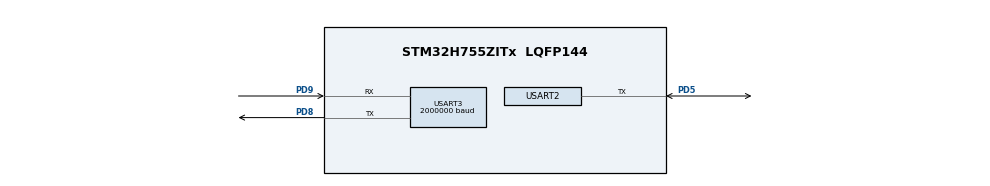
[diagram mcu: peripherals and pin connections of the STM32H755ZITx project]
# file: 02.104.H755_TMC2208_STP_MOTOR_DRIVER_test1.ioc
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CortexM4.IPs=FATFS_M4\:I,FREERTOS_M4\:I,IWDG2\:I,RCC,WWDG2\:I,DMA,BDMA,MDMA,NVIC2\:I,ETH,DEBUG,PDM2PCM_M4\:I,PWR,RESMGR_UTILITY,SYS_M4\:I,USB_DEVICE_M4\:I,USB_HOST_M4\:I,CORTEX_M4\:I,GPIO,OPENAMP_M4\:I,VREFBUF,NUCLEO-H755ZI-Q
CortexM7.IPs=FATFS_M7\:I,FREERTOS_M7\:I,IWDG1\:I,RCC\:I,WWDG1\:I,DMA\:I,BDMA\:I,MDMA\:I,NVIC1\:I,ETH\:I,USART3\:I,USB_OTG_FS\:I,SYS\:I,CORTEX_M7\:I,DEBUG\:I,PDM2PCM_M7\:I,PWR\:I,RESMGR_UTILITY\:I,USB_DEVICE_M7\:I,USB_HOST_M7\:I,GPIO\:I,OPENAMP_M7\:I,VREFBUF\:I,NUCLEO-H755ZI-Q\:I,USART2\:I
Dma.Request0=USART3_TX
Dma.Request1=USART3_RX
Dma.USART3_RX.1.Direction=DMA_PERIPH_TO_MEMORY
Dma.USART3_RX.1.EventEnable=DISABLE
Dma.USART3_RX.1.FIFOMode=DMA_FIFOMODE_DISABLE
Dma.USART3_RX.1.Instance=DMA1_Stream1
Dma.USART3_RX.1.MemDataAlignment=DMA_MDATAALIGN_BYTE
Dma.USART3_RX.1.MemInc=DMA_MINC_ENABLE
Dma.USART3_RX.1.Mode=DMA_CIRCULAR
Dma.USART3_RX.1.PeriphDataAlignment=DMA_PDATAALIGN_BYTE
Dma.USART3_RX.1.PeriphInc=DMA_PINC_DISABLE
Dma.USART3_RX.1.Polarity=HAL_DMAMUX_REQ_GEN_RISING
Dma.USART3_RX.1.Priority=DMA_PRIORITY_LOW
Dma.USART3_RX.1.RequestNumber=1
Dma.USART3_RX.1.SignalID=NONE
Dma.USART3_RX.1.SyncEnable=DISABLE
Dma.USART3_RX.1.SyncPolarity=HAL_DMAMUX_SYNC_NO_EVENT
Dma.USART3_RX.1.SyncRequestNumber=1
Dma.USART3_RX.1.SyncSignalID=NONE
Dma.USART3_TX.0.Direction=DMA_MEMORY_TO_PERIPH
Dma.USART3_TX.0.EventEnable=DISABLE
Dma.USART3_TX.0.FIFOMode=DMA_FIFOMODE_DISABLE
Dma.USART3_TX.0.Instance=DMA1_Stream0
Dma.USART3_TX.0.MemDataAlignment=DMA_MDATAALIGN_BYTE
Dma.USART3_TX.0.MemInc=DMA_MINC_ENABLE
Dma.USART3_TX.0.Mode=DMA_NORMAL
Dma.USART3_TX.0.PeriphDataAlignment=DMA_PDATAALIGN_BYTE
Dma.USART3_TX.0.PeriphInc=DMA_PINC_DISABLE
Dma.USART3_TX.0.Polarity=HAL_DMAMUX_REQ_GEN_RISING
Dma.USART3_TX.0.Priority=DMA_PRIORITY_LOW
Dma.USART3_TX.0.RequestNumber=1
Dma.USART3_TX.0.SignalID=NONE
Dma.USART3_TX.0.SyncEnable=DISABLE
Dma.USART3_TX.0.SyncPolarity=HAL_DMAMUX_SYNC_NO_EVENT
Dma.USART3_TX.0.SyncRequestNumber=1
Dma.USART3_TX.0.SyncSignalID=NONE
Mcu.Family=STM32H7
Mcu.Name=STM32H755ZITx
Mcu.Package=LQFP144
NVIC1.DMA1_Stream0_IRQn=true\:1\:0\:true\:false\:true\:false\:true\:true
NVIC1.DMA1_Stream1_IRQn=true\:1\:0\:true\:false\:true\:false\:true\:true
NVIC1.PriorityGroup=NVIC_PRIORITYGROUP_4
NVIC1.USART2_IRQn=true\:0\:0\:false\:false\:true\:true\:true\:true
NVIC1.USART3_IRQn=true\:1\:0\:true\:false\:true\:true\:true\:true
NVIC2.PriorityGroup=NVIC_PRIORITYGROUP_4
PB0.TagName=LD1
PB14.TagName=LD3
PB6.PinAttribute=CortexM7
PB6.Signal=USART1_TX
PB7.PinAttribute=CortexM7
PB7.Signal=USART1_RX
PC13.TagName=BUTTON
PD5.GPIO_Speed=GPIO_SPEED_FREQ_VERY_HIGH
PD5.Mode=Half_duplex(single_wire_mode)
PD5.PinAttribute=CortexM7
PD5.Signal=USART2_TX
PD6.GPIO_PuPd=GPIO_NOPULL
PD6.GPIO_Speed=GPIO_SPEED_FREQ_VERY_HIGH
PD6.PinAttribute=CortexM7
PD6.Signal=USART2_RX
PD8.Mode=Asynchronous
PD8.PinAttribute=CortexM7
PD8.Signal=USART3_TX
PD8.TagName=VCP_RX
PD9.Mode=Asynchronous
PD9.PinAttribute=CortexM7
PD9.Signal=USART3_RX
PD9.TagName=VCP_TX
PE1.TagName=LD2
ProjectManager.HeapSize=M4-0x200,M7-0x200
ProjectManager.StackSize=M4-0x400,M7-0x400
ProjectManager.TargetToolchain=STM32CubeIDE
RCC.ADCFreq_Value=129000000
RCC.APB1Freq_Value=100000000
RCC.APB2Freq_Value=100000000
RCC.APB3Freq_Value=100000000
RCC.APB4Freq_Value=100000000
RCC.CortexFreq_Value=400000000
RCC.D1PPRE=RCC_APB3_DIV2
RCC.D2PPRE1=RCC_APB1_DIV2
RCC.D2PPRE2=RCC_APB2_DIV2
RCC.D3PPRE=RCC_APB4_DIV2
RCC.DIVM1=4
RCC.DIVN1=50
RCC.DIVQ1=5
RCC.HCLKFreq_Value=200000000
RCC.HPRE=RCC_HCLK_DIV2
RCC.PLL2FRACN=0
RCC.PLL3FRACN=0
RCC.PLLFRACN=0
RCC.SYSCLKFreq_VALUE=400000000
RCC.SYSCLKSource=RCC_SYSCLKSOURCE_PLLCLK
RCC.SupplySource=PWR_DIRECT_SMPS_SUPPLY
RCC.USBFreq_Value=160000000
USART2.VirtualMode-Half_duplex(single_wire_mode)=VM_ASYNC
USART3.BaudRate=2000000
USART3.VirtualMode-Asynchronous=VM_ASYNC
VP_SYS_M4_VS_Systick.Mode=SysTick
board=NUCLEO-H755ZI-Q

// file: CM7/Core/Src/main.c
/* USER CODE BEGIN Header */
/**
  ******************************************************************************
  * @file           : main.c
  * @brief          : Main program body
  ******************************************************************************
  * @attention
  *
  * Copyright (c) 2025 STMicroelectronics.
  * All rights reserved.
  *
  * This software is licensed under terms that can be found in the LICENSE file
  * in the root directory of this software component.
  * If no LICENSE file comes with this software, it is provided AS-IS.
  *
  ******************************************************************************
  */
/* USER CODE END Header */
#include "main.h"

/* USER CODE BEGIN Includes */
#include <stdio.h>
#include <string.h>
#include <stddef.h>
#include <stdarg.h>
#include <stdbool.h>
#include <stdlib.h>
/* USER CODE END Includes */

/* USER CODE BEGIN PD */

/* DUAL_CORE_BOOT_SYNC_SEQUENCE: Define for dual core boot synchronization    */
/*                             demonstration code based on hardware semaphore */
/* This define is present in both CM7/CM4 projects                            */
/* To comment when developping/debugging on a single core                     */
#define DUAL_CORE_BOOT_SYNC_SEQUENCE

#if defined(DUAL_CORE_BOOT_SYNC_SEQUENCE)
#ifndef HSEM_ID_0
#define HSEM_ID_0 (0U) /* HW semaphore 0*/
#endif
#endif /* DUAL_CORE_BOOT_SYNC_SEQUENCE */

/* USER CODE END PD */

UART_HandleTypeDef huart4;
UART_HandleTypeDef huart3;
DMA_HandleTypeDef hdma_usart3_tx;
DMA_HandleTypeDef hdma_usart3_rx;

/* USER CODE BEGIN PV */
uint8_t dma_rx_buffer[64];
uint8_t dma_tx_buffer[64];
uint16_t old_pos = 0;

static volatile bool uart_tx_busy = false;
static char uartBuffer[250];

typedef enum
{
    TMC_IDLE,
    TMC_TX,
    TMC_WAIT_TURNAROUND,
    TMC_RX,
    TMC_DONE,
    TMC_ERROR
} TMC_State_t;

volatile TMC_State_t tmcState = TMC_IDLE;
uint32_t tmcTimestamp;

uint8_t tmc_tx[8];
uint8_t tmc_rx[8];

/* USER CODE END PV */

void SystemClock_Config(void);
static void MX_GPIO_Init(void);
static void MX_DMA_Init(void);
static void MX_USART3_UART_Init(void);
static void MX_USART2_UART_Init(void);

/* USER CODE BEGIN 0 */
void DebugPrint(const char *format, ...)
{
	// Wait for previous transmission to complete
	    while (uart_tx_busy);

	    va_list args;
	    va_start(args, format);
	    vsnprintf(uartBuffer, sizeof(uartBuffer), format, args);
	    va_end(args);

	    uart_tx_busy = true;

	    HAL_UART_Transmit_DMA(&huart3, (uint8_t *)uartBuffer, strlen(uartBuffer));
}

void UART2_TX_Output(void)
{
    GPIO_InitTypeDef GPIO_InitStruct = {0};

    GPIO_InitStruct.Pin       = GPIO_PIN_5;
    GPIO_InitStruct.Mode      = GPIO_MODE_AF_PP;
    GPIO_InitStruct.Pull      = GPIO_NOPULL;
    GPIO_InitStruct.Speed     = GPIO_SPEED_FREQ_HIGH;
    GPIO_InitStruct.Alternate = GPIO_AF7_USART2;

    HAL_GPIO_Init(GPIOD, &GPIO_InitStruct);
}

void UART2_TX_Input(void)
{
    GPIO_InitTypeDef GPIO_InitStruct = {0};

    GPIO_InitStruct.Pin  = GPIO_PIN_5;
    GPIO_InitStruct.Mode = GPIO_MODE_INPUT;
    GPIO_InitStruct.Pull = GPIO_NOPULL;

    HAL_GPIO_Init(GPIOD, &GPIO_InitStruct);
}

void parse_tmc_response(uint8_t *data)
{
	DebugPrint("TMC: ");
    for (int i = 0; i < 8; i++)
    	DebugPrint("%02X ", data[i]);
    DebugPrint("\r\n");
}

uint8_t tmc2208_crc(uint8_t *data, uint8_t len)
{
    uint8_t crc = 0;

    for (uint8_t i = 0; i < len; i++)
    {
        uint8_t current = data[i];
        for (uint8_t bit = 0; bit < 8; bit++)
        {
            if ((crc ^ current) & 0x01)
                crc = (crc >> 1) ^ 0x8C;
            else
                crc >>= 1;

            current >>= 1;
        }
    }
    return crc;
}

void build_tmc_frame(uint8_t *buf)
{
    buf[0] = 0x05;     // SYNC
    buf[1] = 0x00;     // Slave address
    buf[2] = 0x00;     // GCONF
    buf[3] = 0x00;
    buf[4] = 0x00;
    buf[5] = 0x00;
    buf[6] = 0x00;

    buf[7] = 0x07;
//    buf[7] = tmc2208_crc(buf, 7);
}

void TMC2208_StartRead(void)
{
    if (tmcState == TMC_IDLE)
    {
        build_tmc_frame(tmc_tx);
        tmcState = TMC_TX;
    }
}

void check_dma_data(void)
{
    static uint32_t total_pos = 0;  // new: global linear counter

    uint16_t pos = sizeof(dma_rx_buffer) - __HAL_DMA_GET_COUNTER(&hdma_usart3_rx);

    if (pos != old_pos)
    {
        if (pos > old_pos)
        {
            // Normal forward move (no wrap)
            for (uint16_t i = old_pos; i < pos; i++)
            {
                DebugPrint("\r\nGot: '%c' (0x%02X) at pos %lu\r\n\r\n",
                           dma_rx_buffer[i], dma_rx_buffer[i], total_pos++);
            }
        }
        else
        {
            // Wrapped around — handle end part and restart from 0
            for (uint16_t i = old_pos; i < sizeof(dma_rx_buffer); i++)
            {
                DebugPrint("\r\nGot: '%c' (0x%02X) at pos %lu\r\n\r\n",
                           dma_rx_buffer[i], dma_rx_buffer[i], total_pos++);
            }
            for (uint16_t i = 0; i < pos; i++)
            {
                DebugPrint("\r\nGot: '%c' (0x%02X) at pos %lu\r\n\r\n",
                           dma_rx_buffer[i], dma_rx_buffer[i], total_pos++);
            }
        }

        old_pos = pos;
    }
}

void TMC2208_Process(void)
{
    switch (tmcState)
    {
        case TMC_IDLE:
            break;

        case TMC_TX:
            UART2_TX_Output();
            HAL_UART_Transmit_IT(&huart4, tmc_tx, 8);
            break;

        case TMC_WAIT_TURNAROUND:
            if ((HAL_GetTick() - tmcTimestamp) >= 5)
            {
            	DebugPrint("C\n\r");
                UART2_TX_Input();
                HAL_UART_Receive_IT(&huart4, tmc_rx, 8);
                tmcState = TMC_RX;
                DebugPrint("D\n\r");
            }
            break;

        case TMC_RX:
            /* wait for callback */
            break;

        case TMC_DONE:
            parse_tmc_response(tmc_rx);

            DebugPrint("E\n\r");
            tmcState = TMC_IDLE;
            break;

        case TMC_ERROR:
            tmcState = TMC_IDLE;
            break;
    }
}

/* USER CODE END 0 */

int main(void)
{

/* USER CODE BEGIN Boot_Mode_Sequence_0 */
#if defined(DUAL_CORE_BOOT_SYNC_SEQUENCE)
  int32_t timeout;
#endif /* DUAL_CORE_BOOT_SYNC_SEQUENCE */
/* USER CODE END Boot_Mode_Sequence_0 */

/* USER CODE BEGIN Boot_Mode_Sequence_1 */
#if defined(DUAL_CORE_BOOT_SYNC_SEQUENCE)
  /* Wait until CPU2 boots and enters in stop mode or timeout*/
  timeout = 0xFFFF;
  while((__HAL_RCC_GET_FLAG(RCC_FLAG_D2CKRDY) != RESET) && (timeout-- > 0));
  if ( timeout < 0 )
  {
  Error_Handler();
  }
#endif /* DUAL_CORE_BOOT_SYNC_SEQUENCE */
/* USER CODE END Boot_Mode_Sequence_1 */
  /* MCU Configuration--------------------------------------------------------*/

  /* Reset of all peripherals, Initializes the Flash interface and the Systick. */
  HAL_Init();

  /* Configure the system clock */
  SystemClock_Config();
/* USER CODE BEGIN Boot_Mode_Sequence_2 */
#if defined(DUAL_CORE_BOOT_SYNC_SEQUENCE)
/* When system initialization is finished, Cortex-M7 will release Cortex-M4 by means of
HSEM notification */
/*HW semaphore Clock enable*/
__HAL_RCC_HSEM_CLK_ENABLE();
/*Take HSEM */
HAL_HSEM_FastTake(HSEM_ID_0);
/*Release HSEM in order to notify the CPU2(CM4)*/
HAL_HSEM_Release(HSEM_ID_0,0);
/* wait until CPU2 wakes up from stop mode */
timeout = 0xFFFF;
while((__HAL_RCC_GET_FLAG(RCC_FLAG_D2CKRDY) == RESET) && (timeout-- > 0));
if ( timeout < 0 )
{
Error_Handler();
}
#endif /* DUAL_CORE_BOOT_SYNC_SEQUENCE */
/* USER CODE END Boot_Mode_Sequence_2 */

  /* Initialize all configured peripherals */
  MX_GPIO_Init();
  MX_DMA_Init();
  MX_USART3_UART_Init();
  MX_USART2_UART_Init();
  /* USER CODE BEGIN 2 */
  DebugPrint("\r\n=== UART DMA RX Circular + TX Normal ===\r\n");

  HAL_UART_Receive_DMA(&huart3, dma_rx_buffer, sizeof(dma_rx_buffer));

  uint8_t test[7] = {0x05,0x00,0x00,0x00,0x00,0x00,0x00};
  uint8_t crc = tmc2208_crc(test, 7);

  DebugPrint("crc: %x\n\r",crc);

  /* USER CODE END 2 */

  /* Infinite loop */
  while (1)
  {

    /* USER CODE BEGIN 3 */
	  check_dma_data();

      TMC2208_Process();

      /* Trigger read periodically */
      static uint32_t last = 0;
      if (HAL_GetTick() - last > 100)
      {
          last = HAL_GetTick();
          TMC2208_StartRead();
      }
  }
  /* USER CODE END 3 */
}

void SystemClock_Config(void)
{
  RCC_OscInitTypeDef RCC_OscInitStruct = {0};
  RCC_ClkInitTypeDef RCC_ClkInitStruct = {0};

  /** Supply configuration update enable
  */
  HAL_PWREx_ConfigSupply(PWR_DIRECT_SMPS_SUPPLY);

  /** Configure the main internal regulator output voltage
  */
  __HAL_PWR_VOLTAGESCALING_CONFIG(PWR_REGULATOR_VOLTAGE_SCALE1);

  while(!__HAL_PWR_GET_FLAG(PWR_FLAG_VOSRDY)) {}

  /** Initializes the RCC Oscillators according to the specified parameters
  * in the RCC_OscInitTypeDef structure.
  */
  RCC_OscInitStruct.OscillatorType = RCC_OSCILLATORTYPE_HSI;
  RCC_OscInitStruct.HSIState = RCC_HSI_DIV1;
  RCC_OscInitStruct.HSICalibrationValue = RCC_HSICALIBRATION_DEFAULT;
  RCC_OscInitStruct.PLL.PLLState = RCC_PLL_ON;
  RCC_OscInitStruct.PLL.PLLSource = RCC_PLLSOURCE_HSI;
  RCC_OscInitStruct.PLL.PLLM = 4;
  RCC_OscInitStruct.PLL.PLLN = 50;
  RCC_OscInitStruct.PLL.PLLP = 2;
  RCC_OscInitStruct.PLL.PLLQ = 5;
  RCC_OscInitStruct.PLL.PLLR = 2;
  RCC_OscInitStruct.PLL.PLLRGE = RCC_PLL1VCIRANGE_3;
  RCC_OscInitStruct.PLL.PLLVCOSEL = RCC_PLL1VCOWIDE;
  RCC_OscInitStruct.PLL.PLLFRACN = 0;
  if (HAL_RCC_OscConfig(&RCC_OscInitStruct) != HAL_OK)
  {
    Error_Handler();
  }

  /** Initializes the CPU, AHB and APB buses clocks
  */
  RCC_ClkInitStruct.ClockType = RCC_CLOCKTYPE_HCLK|RCC_CLOCKTYPE_SYSCLK
                              |RCC_CLOCKTYPE_PCLK1|RCC_CLOCKTYPE_PCLK2
                              |RCC_CLOCKTYPE_D3PCLK1|RCC_CLOCKTYPE_D1PCLK1;
  RCC_ClkInitStruct.SYSCLKSource = RCC_SYSCLKSOURCE_PLLCLK;
  RCC_ClkInitStruct.SYSCLKDivider = RCC_SYSCLK_DIV1;
  RCC_ClkInitStruct.AHBCLKDivider = RCC_HCLK_DIV2;
  RCC_ClkInitStruct.APB3CLKDivider = RCC_APB3_DIV2;
  RCC_ClkInitStruct.APB1CLKDivider = RCC_APB1_DIV2;
  RCC_ClkInitStruct.APB2CLKDivider = RCC_APB2_DIV2;
  RCC_ClkInitStruct.APB4CLKDivider = RCC_APB4_DIV2;

  if (HAL_RCC_ClockConfig(&RCC_ClkInitStruct, FLASH_LATENCY_2) != HAL_OK)
  {
    Error_Handler();
  }
}

static void MX_USART2_UART_Init(void)
{

  huart4.Instance = USART2;
  huart4.Init.BaudRate = 115200;
  huart4.Init.WordLength = UART_WORDLENGTH_8B;
  huart4.Init.StopBits = UART_STOPBITS_1;
  huart4.Init.Parity = UART_PARITY_NONE;
  huart4.Init.Mode = UART_MODE_TX_RX;
  huart4.Init.HwFlowCtl = UART_HWCONTROL_NONE;
  huart4.Init.OverSampling = UART_OVERSAMPLING_16;
  huart4.Init.OneBitSampling = UART_ONE_BIT_SAMPLE_DISABLE;
  huart4.Init.ClockPrescaler = UART_PRESCALER_DIV1;
  huart4.AdvancedInit.AdvFeatureInit = UART_ADVFEATURE_NO_INIT;
  if (HAL_HalfDuplex_Init(&huart4) != HAL_OK)
  {
    Error_Handler();
  }
  if (HAL_UARTEx_SetTxFifoThreshold(&huart4, UART_TXFIFO_THRESHOLD_1_8) != HAL_OK)
  {
    Error_Handler();
  }
  if (HAL_UARTEx_SetRxFifoThreshold(&huart4, UART_RXFIFO_THRESHOLD_1_8) != HAL_OK)
  {
    Error_Handler();
  }
  if (HAL_UARTEx_DisableFifoMode(&huart4) != HAL_OK)
  {
    Error_Handler();
  }

}

static void MX_USART3_UART_Init(void)
{

  huart3.Instance = USART3;
  huart3.Init.BaudRate = 2000000;
  huart3.Init.WordLength = UART_WORDLENGTH_8B;
  huart3.Init.StopBits = UART_STOPBITS_1;
  huart3.Init.Parity = UART_PARITY_NONE;
  huart3.Init.Mode = UART_MODE_TX_RX;
  huart3.Init.HwFlowCtl = UART_HWCONTROL_NONE;
  huart3.Init.OverSampling = UART_OVERSAMPLING_16;
  huart3.Init.OneBitSampling = UART_ONE_BIT_SAMPLE_DISABLE;
  huart3.Init.ClockPrescaler = UART_PRESCALER_DIV1;
  huart3.AdvancedInit.AdvFeatureInit = UART_ADVFEATURE_NO_INIT;
  if (HAL_UART_Init(&huart3) != HAL_OK)
  {
    Error_Handler();
  }
  if (HAL_UARTEx_SetTxFifoThreshold(&huart3, UART_TXFIFO_THRESHOLD_1_8) != HAL_OK)
  {
    Error_Handler();
  }
  if (HAL_UARTEx_SetRxFifoThreshold(&huart3, UART_RXFIFO_THRESHOLD_1_8) != HAL_OK)
  {
    Error_Handler();
  }
  if (HAL_UARTEx_DisableFifoMode(&huart3) != HAL_OK)
  {
    Error_Handler();
  }

}

static void MX_DMA_Init(void)
{

  /* DMA controller clock enable */
  __HAL_RCC_DMA1_CLK_ENABLE();

  /* DMA interrupt init */
  /* DMA1_Stream0_IRQn interrupt configuration */
  HAL_NVIC_SetPriority(DMA1_Stream0_IRQn, 1, 0);
  HAL_NVIC_EnableIRQ(DMA1_Stream0_IRQn);
  /* DMA1_Stream1_IRQn interrupt configuration */
  HAL_NVIC_SetPriority(DMA1_Stream1_IRQn, 1, 0);
  HAL_NVIC_EnableIRQ(DMA1_Stream1_IRQn);

}

static void MX_GPIO_Init(void)
{
  GPIO_InitTypeDef GPIO_InitStruct = {0};

  /* GPIO Ports Clock Enable */
  __HAL_RCC_GPIOD_CLK_ENABLE();
  __HAL_RCC_GPIOB_CLK_ENABLE();

  /*Configure GPIO pins : PB6 PB7 */
  GPIO_InitStruct.Pin = GPIO_PIN_6|GPIO_PIN_7;
  GPIO_InitStruct.Mode = GPIO_MODE_AF_PP;
  GPIO_InitStruct.Pull = GPIO_NOPULL;
  GPIO_InitStruct.Speed = GPIO_SPEED_FREQ_LOW;
  GPIO_InitStruct.Alternate = GPIO_AF7_USART1;
  HAL_GPIO_Init(GPIOB, &GPIO_InitStruct);

}

/* USER CODE BEGIN 4 */
void HAL_UART_TxCpltCallback(UART_HandleTypeDef *huart)
{
    if (huart->Instance == USART3)
    {
        uart_tx_busy = false;  // Transmission complete
    }

    if (huart->Instance == USART2)
    {
    	DebugPrint("A\n\r");
        tmcState = TMC_WAIT_TURNAROUND;
        tmcTimestamp = HAL_GetTick();
    }
}

void HAL_UART_RxCpltCallback(UART_HandleTypeDef *huart)
{
    if (huart->Instance == USART2)
    {
    	DebugPrint("B\n\r");
        tmcState = TMC_DONE;
    }
}

/* USER CODE END 4 */

void Error_Handler(void)
{
  __disable_irq();
  while (1)
  {
  }
}
